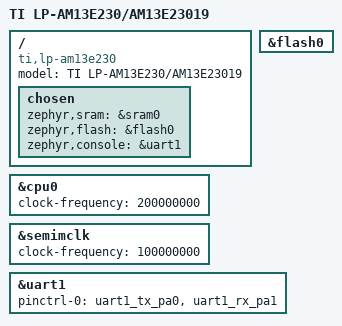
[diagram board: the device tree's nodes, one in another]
/* SPDX-License-Identifier: Apache-2.0 */

/dts-v1/;

#include <ti/am13e23019.dtsi>
#include "lp_am13e230-pinctrl.dtsi"

/ {
	model = "TI LP-AM13E230/AM13E23019";
	compatible = "ti,lp-am13e230", "ti,am13e23019";

	chosen {
		zephyr,sram = &sram0;
		zephyr,flash = &flash0;

		zephyr,console = &uart1;
	};
};

&cpu0 {
	clock-frequency = <200000000>;
};

&semimclk {
	clock-frequency = <100000000>;
};

&flash0 {
	status = "okay";
};

&uart1 {
	pinctrl-0 = <&uart1_tx_pa0 &uart1_rx_pa1>;
	pinctrl-names = "default";
	status = "okay";
};
